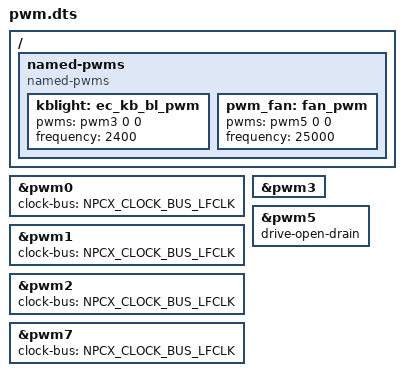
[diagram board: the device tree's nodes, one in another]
/* Copyright 2021 The Chromium OS Authors. All rights reserved.
 * Use of this source code is governed by a BSD-style license that can be
 * found in the LICENSE file.
 */

/ {
	named-pwms {
		compatible = "named-pwms";

		kblight: ec_kb_bl_pwm {
			pwms = <&pwm3 0 0>;
			frequency = <2400>;
		};
		pwm_fan: fan_pwm {
			pwms = <&pwm5 0 0>;
			frequency = <25000>;
		};
	};
};

/* Green LED */
&pwm0 {
	status = "okay";
	clock-bus = "NPCX_CLOCK_BUS_LFCLK";
};

/* Red LED */
&pwm1 {
	status = "okay";
	clock-bus = "NPCX_CLOCK_BUS_LFCLK";
};

/* Blue LED */
&pwm2 {
	status = "okay";
	clock-bus = "NPCX_CLOCK_BUS_LFCLK";
};

/* Keyboard backlight */
&pwm3 {
	status = "okay";
};

/* Fan control */
&pwm5 {
	status = "okay";
	drive-open-drain;
};

/* Side selection LED */
&pwm7 {
	status = "okay";
	clock-bus = "NPCX_CLOCK_BUS_LFCLK";
};
